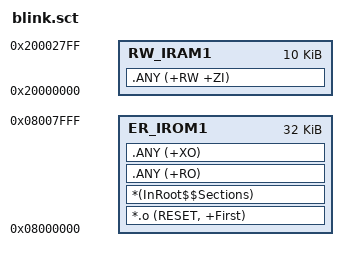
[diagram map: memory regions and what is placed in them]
; STM32F103C8?????32K Flash / 10K RAM?? ARMCLANG / armlink ????????
LR_IROM1 0x08000000 0x00008000  {          ; ????32 KiB Flash
  ER_IROM1 0x08000000 0x00008000  {        ; ???????
   *.o (RESET, +First)                     ; ??????? 0x08000000
   *(InRoot$$Sections)                     ; __main ???
   .ANY (+RO)                              ; ??????? + ???
   .ANY (+XO)                              ; ?????
  }
  RW_IRAM1 0x20000000 0x00002800  {        ; ????10 KiB RAM
   .ANY (+RW +ZI)
  }
}
